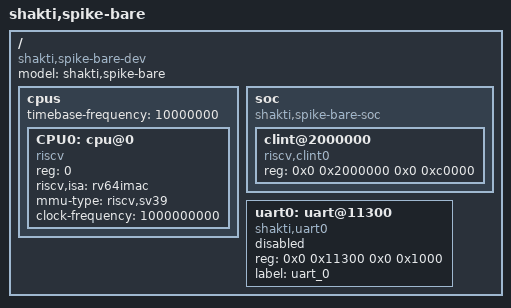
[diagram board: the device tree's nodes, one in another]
/ {
#address-cells = <2>;
#size-cells = <2>;
	compatible = "shakti,spike-bare-dev";
	model = "shakti,spike-bare";
	cpus {
		#address-cells = <1>;
		#size-cells = <0>;
		timebase-frequency = <10000000>;
CPU0: cpu@0 {
	      device_type = "cpu";
	      reg = <0>;
	      status = "okay";
	      compatible = "riscv";
	      riscv,isa = "rv64imac";
	      mmu-type = "riscv,sv39";
	      clock-frequency = <1000000000>;

	      };
	};


	soc {
		#address-cells = <2>;
		#size-cells = <2>;
		compatible = "shakti,spike-bare-soc", "simple-bus";
		ranges;
		clint@2000000 {
			compatible = "riscv,clint0";
			reg = <0x0 0x2000000 0x0 0xc0000>;
		};
	};
       
   
uart0: uart@11300 {
	       compatible = "shakti,uart0";
	       reg= < 0x0 0x11300 0x0 0x1000>;
	       reg-names = "control";
	       label = "uart_0";
	       status = "disabled";
       };
};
